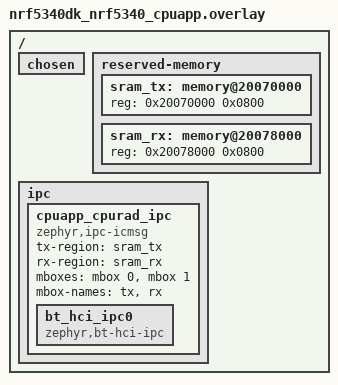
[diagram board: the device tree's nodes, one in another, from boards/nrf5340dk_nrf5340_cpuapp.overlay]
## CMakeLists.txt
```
#
# Copyright (c) 2025 Nordic Semiconductor ASA
#
# SPDX-License-Identifier: LicenseRef-Nordic-5-Clause
#

cmake_minimum_required(VERSION 3.20.0)

find_package(Zephyr REQUIRED HINTS $ENV{ZEPHYR_BASE})
project(zbus_ipc_forwarder)

zephyr_library_include_directories(
    src
    common
)

# Define which device this is
zephyr_compile_definitions(ZBUS_DEVICE_A=1)

target_sources(app PRIVATE src/main.c)
```

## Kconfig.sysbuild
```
#
# Copyright (c) 2025 Nordic Semiconductor ASA
#
# SPDX-License-Identifier: LicenseRef-Nordic-5-Clause
#

source "share/sysbuild/Kconfig"

choice 
	prompt "Remote board target"
	default REMOTE_BOARD_NRF54H20_CPURAD if BOARD = "nrf54h20dk"
	default REMOTE_BOARD_NRF5340_CPUNET if BOARD = "nrf5340dk"
	
config REMOTE_BOARD_NRF54H20_CPURAD
	bool "nrf54h20dk/nrf54h20/cpurad"

config REMOTE_BOARD_NRF54H20_CPUPPR
	bool "nrf54h20dk/nrf54h20/cpuppr"

config REMOTE_BOARD_NRF54H20_CPUPPR_XIP
	bool "nrf54h20dk/nrf54h20/cpuppr/xip"

## Do not fit on nRF54H20_CPUFLPR without XIP

config REMOTE_BOARD_NRF54H20_CPUFLPR_XIP
	bool "nrf54h20dk/nrf54h20/cpuflpr/xip"

config REMOTE_BOARD_NRF5340_CPUNET
	bool "nrf5340dk/nrf5340/cpunet"

endchoice

config REMOTE_BOARD
	string "The board used for remote target"
	default "nrf54h20dk/nrf54h20/cpurad" if REMOTE_BOARD_NRF54H20_CPURAD
	default "nrf54h20dk/nrf54h20/cpuppr" if REMOTE_BOARD_NRF54H20_CPUPPR
	default "nrf54h20dk/nrf54h20/cpuppr/xip" if REMOTE_BOARD_NRF54H20_CPUPPR_XIP
	default "nrf54h20dk/nrf54h20/cpuflpr/xip" if REMOTE_BOARD_NRF54H20_CPUFLPR_XIP
	default "nrf5340dk/nrf5340/cpunet" if REMOTE_BOARD_NRF5340_CPUNET
```

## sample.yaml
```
sample:
  name: ZBus multicore example (IPC backend)
common:
  timeout: 30
tests:
  sample.zbus.ipc_forwarder:
    platform_allow:
      - nrf54h20dk/nrf54h20/cpuapp
      - nrf5340dk/nrf5340/cpuapp
    integration_platforms:
      - nrf54h20dk/nrf54h20/cpuapp
      - nrf5340dk/nrf5340/cpuapp
    tags: zbus
    sysbuild: true
    harness: console
    harness_config:
      type: multi_line
      ordered: false
      regex:
        - "I: .*/cpuapp started"
        - "I: Received message from domain 'nrf(54h20|5340)/cpuapp': cnt=0, str='Hello from CPUAPP'"
        - "I: Received message from domain 'nrf(54h20|5340)/cpu(rad|net)': cnt=0, str='Hello from CPUAPP'"
        - "I: Received message from domain 'nrf(54h20|5340)/cpuapp': cnt=1, str='Hello from CPUAPP'"
        - "I: Received message from domain 'nrf(54h20|5340)/cpu(rad|net)': cnt=1, str='Hello from CPUAPP'"
```

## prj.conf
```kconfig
# Copyright (c) 2025 Nordic Semiconductor ASA
# SPDX-License-Identifier: LicenseRef-Nordic-5-Clause


CONFIG_LOG=y
# CONFIG_LOG_MODE_MINIMAL=y
CONFIG_LOG_DBG_COLOR_BLUE=y

CONFIG_HEAP_MEM_POOL_SIZE=4096

CONFIG_ZBUS=y

CONFIG_MBOX=y
CONFIG_IPC_SERVICE=y

CONFIG_ZBUS_MULTIDOMAIN=y
CONFIG_ZBUS_MULTIDOMAIN_IPC=y
CONFIG_ZBUS_MULTIDOMAIN_LOG_LEVEL_DBG=n

# Increase the size of the receive buffer to accommodate larger messages
CONFIG_PBUF_RX_READ_BUF_SIZE=384
```

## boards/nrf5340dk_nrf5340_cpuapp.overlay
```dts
/*
 * Copyright (c) 2022 Nordic Semiconductor ASA
 *
 * SPDX-License-Identifier: Apache-2.0
 */

/ {
	chosen {
		/delete-property/ zephyr,ipc_shm;
		/delete-property/ nordic,802154-spinel-ipc;
	};

	reserved-memory {
		/delete-node/ memory@20070000;

		sram_tx: memory@20070000 {
			reg = <0x20070000 0x0800>;
		};

		sram_rx: memory@20078000 {
			reg = <0x20078000 0x0800>;
		};
	};

	ipc {
		/delete-node/ ipc0;

		cpuapp_cpurad_ipc: cpuapp_cpurad_ipc {
			compatible = "zephyr,ipc-icmsg";
			tx-region = <&sram_tx>;
			rx-region = <&sram_rx>;
			mboxes = <&mbox 0>, <&mbox 1>;
			mbox-names = "tx", "rx";
			status = "okay";

			bt_hci_ipc0: bt_hci_ipc0 {
				compatible = "zephyr,bt-hci-ipc";
				status = "okay";
			};
		};
	};
};
```

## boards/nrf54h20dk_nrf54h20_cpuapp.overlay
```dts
/*
 * Copyright (c) 2025 Nordic Semiconductor ASA
 * SPDX-License-Identifier: LicenseRef-Nordic-5-Clause
 */

&cpuapp_bellboard {
	status = "okay";
};

/ {
	chosen {
		/delete-property/ zephyr,bt-hci;
	};
};
```

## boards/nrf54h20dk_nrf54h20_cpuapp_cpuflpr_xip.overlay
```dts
/*
 * Copyright (c) 2025 Nordic Semiconductor ASA
 * SPDX-License-Identifier: LicenseRef-Nordic-5-Clause
 */

 /* Setup for cpuapp_cpuflpr_ipc */
&cpuapp_bellboard {
	status = "okay";
};

/delete-node/ &cpuapp_cpurad_ipc;

ipc0: &cpuapp_cpuflpr_ipc {
	status = "okay";
};

&cpuflpr_vevif {
	status = "okay";
};

/ {
	chosen {
		/delete-property/ zephyr,bt-hci;
	};
};

/* Necessary for the cpuflpr_xip to work */
&cpuflpr_vpr {
	status = "okay";
	execution-memory = <&cpuflpr_code_partition>;
	/delete-property/ source-memory;
};

&uart120 {
	status = "reserved";
	interrupt-parent = <&cpuflpr_clic>;
};
```

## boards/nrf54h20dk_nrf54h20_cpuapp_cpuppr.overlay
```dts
/*
 * Copyright (c) 2025 Nordic Semiconductor ASA
 * SPDX-License-Identifier: LicenseRef-Nordic-5-Clause
 */

 /* Setup for cpuapp_cpuppr_ipc */
&cpuapp_bellboard {
	status = "okay";
};

/delete-node/ &cpuapp_cpurad_ipc;

ipc0: &cpuapp_cpuppr_ipc {
	status = "okay";
};

&cpuppr_vevif {
	status = "okay";
};

/ {
	chosen {
		/delete-property/ zephyr,bt-hci;
	};
};

/* Necessary for the cpuppr to work */
&cpuppr_vpr {
	status = "okay";
};

&cpuppr_ram3x_region {
	status = "okay";
};

&uart135 {
	status = "reserved";
};
```

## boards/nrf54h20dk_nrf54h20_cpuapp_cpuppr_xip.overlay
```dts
/*
 * Copyright (c) 2025 Nordic Semiconductor ASA
 * SPDX-License-Identifier: LicenseRef-Nordic-5-Clause
 */

 /* Setup for cpuapp_cpuppr_ipc */
&cpuapp_bellboard {
	status = "okay";
};

/delete-node/ &cpuapp_cpurad_ipc;

ipc0: &cpuapp_cpuppr_ipc {
	status = "okay";
};

&cpuppr_vevif {
	status = "okay";
};

/ {
	chosen {
		/delete-property/ zephyr,bt-hci;
	};
};

/* Necessary for the cpuppr_xip to work */
&cpuppr_vpr {
	status = "okay";
	execution-memory = <&cpuppr_code_partition>;
	/delete-property/ source-memory;
};

&cpuppr_ram3x_region {
	status = "okay";
};

&uart135 {
	status = "reserved";
};
```

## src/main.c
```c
#include <zephyr/kernel.h>
#include <zephyr/logging/log.h>
#include <string.h>
#include <zephyr/zbus/zbus.h>
#include <zephyr/zbus/multidomain/zbus_multidomain.h>

#include "common.h"

LOG_MODULE_REGISTER(main, LOG_LEVEL_DBG);

/* NOTE: Shared channels request_channel and response_channel are defined in common.h */

/* Set up proxy agent for ipc0 and add response channel to be forwarded */
ZBUS_PROXY_AGENT_DEFINE(ipc_proxy, ZBUS_MULTIDOMAIN_TYPE_IPC, ipc0);
ZBUS_PROXY_ADD_CHANNEL(ipc_proxy, request_channel);

/* Log response data coming from the response channel */
void ipc_forwarder_listener_cb(const struct zbus_channel *chan)
{
	LOG_INF("Received message on channel %s", chan->name);
	const struct response_data *data = zbus_chan_const_msg(chan);
	LOG_INF("Response ID: %d, Value: %d", data->response_id, data->value);
}
ZBUS_LISTENER_DEFINE(ipc_forwarder_listener, ipc_forwarder_listener_cb);
ZBUS_CHAN_ADD_OBS(response_channel, ipc_forwarder_listener, 0);

bool print_channel_info(const struct zbus_channel *chan)
{
	if (chan == NULL) {
		LOG_ERR("Channel is NULL");
		return false;
	}
	LOG_INF("Channel %s is a %s channel", chan->name,
		ZBUS_CHANNEL_IS_SHADOW(chan) ? "shadow" : "master");
	return true;
}

int main(void)
{
	LOG_INF("ZBUS Multidomain IPC Forwarder Sample Application");
	zbus_iterate_over_channels(print_channel_info);

	struct request_data data = {.request_id = 1, .min_value = -1, .max_value = 1};

	while (1) {

		int ret = zbus_chan_pub(&request_channel, &data, K_MSEC(100));
		if (ret < 0) {
			LOG_ERR("Failed to publish on channel %s: %d", request_channel.name, ret);
		} else {
			LOG_INF("Published on channel %s. Request ID=%d, Min=%d, Max=%d",
				request_channel.name, data.request_id, data.min_value,
				data.max_value);
		}

		data.request_id++;
		data.min_value -= 1;
		data.max_value += 1;
		k_sleep(K_SECONDS(5));
	}
	return 0;
}
```
